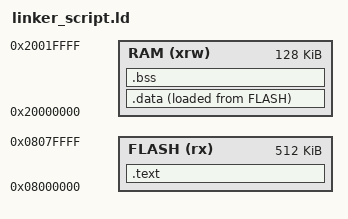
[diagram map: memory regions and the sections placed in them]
MEMORY
{
    FLASH (rx) : ORIGIN = 0x08000000, LENGTH = 512K
    RAM  (xrw) : ORIGIN = 0x20000000, LENGTH = 128K
}

_estack = ORIGIN(RAM) + LENGTH(RAM);

SECTIONS
{
    .text : {
        *(.isr_vector)
        *(.text)
        *(.rodata)
        _etext = .;
    } > FLASH

    _sidata = LOADADDR(.data);
    .data : {
        _sdata = .;
        *(.data)
        _edata = .;
    } > RAM AT > FLASH

    .bss : {
        _sbss = .;
        *(.bss)
        _ebss = .;
    } > RAM
}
